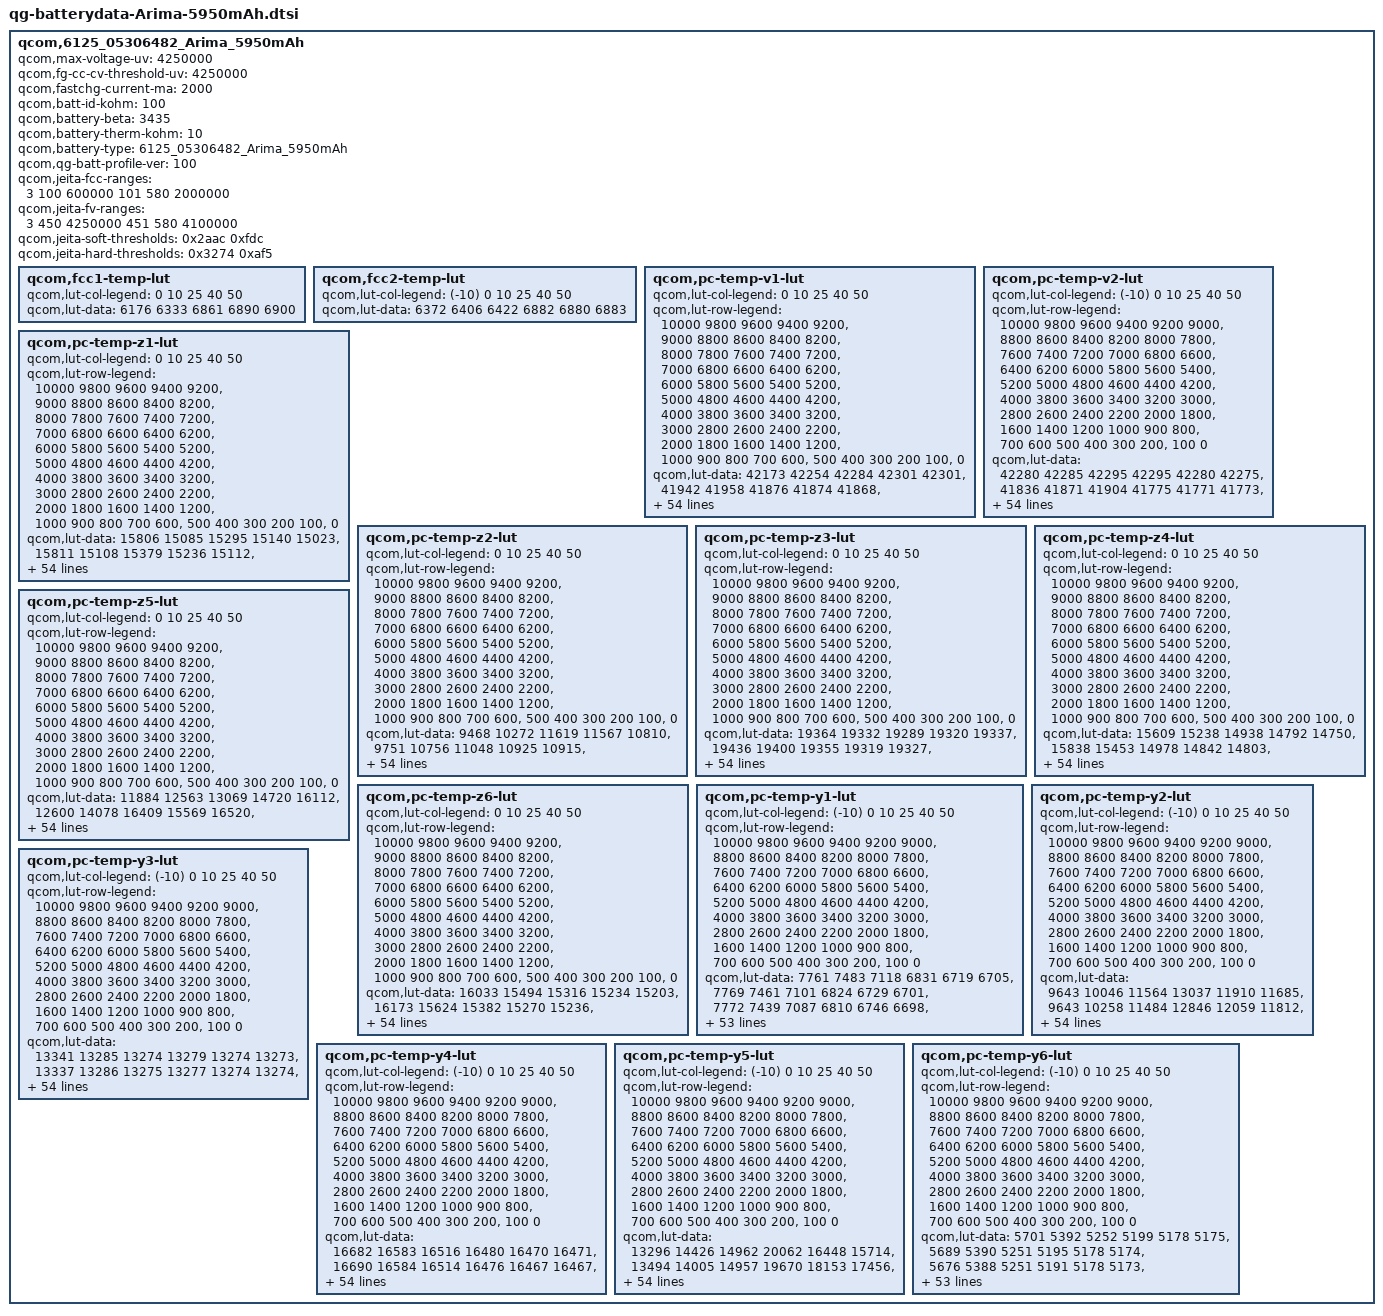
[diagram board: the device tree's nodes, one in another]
/* Copyright (c) 2022, Qualcomm Innovation Center, Inc. All rights reserved.
 *
 * This program is free software; you can redistribute it and/or modify
 * it under the terms of the GNU General Public License version 2 and
 * only version 2 as published by the Free Software Foundation.
 *
 * This program is distributed in the hope that it will be useful,
 * but WITHOUT ANY WARRANTY; without even the implied warranty of
 * MERCHANTABILITY or FITNESS FOR A PARTICULAR PURPOSE.  See the
 * GNU General Public License for more details.
 */

qcom,6125_05306482_Arima_5950mAh {
	/* 6125_05306482_Arima_5950mAh_averaged_MasterSlave_Oct2nd2021 */
	qcom,max-voltage-uv = <4250000>;
	qcom,fg-cc-cv-threshold-uv = <4250000>;
	qcom,fastchg-current-ma = <2000>;
	qcom,batt-id-kohm = <100>;
	qcom,battery-beta = <3435>;
	qcom,battery-therm-kohm = <10>;
	qcom,battery-type = "6125_05306482_Arima_5950mAh";
	qcom,qg-batt-profile-ver = <100>;
	qcom,jeita-fcc-ranges = <3   100   600000
				101 580  2000000>;

	qcom,jeita-fv-ranges =  <3   450  4250000
				451 580  4100000>;
	/* COOL = 10 DegC, WARM = 45 DegC */
	qcom,jeita-soft-thresholds = <0x2aac 0xfdc>;
	/* COLD = 3 DegC, HOT = 58 DegC */
	qcom,jeita-hard-thresholds = <0x3274 0xaf5>;

	qcom,fcc1-temp-lut {
		qcom,lut-col-legend = <0 10 25 40 50>;
		qcom,lut-data = <6176 6333 6861 6890 6900>;
	};

	qcom,fcc2-temp-lut {
		qcom,lut-col-legend = <(-10) 0 10 25 40 50>;
		qcom,lut-data = <6372 6406 6422 6882 6880 6883>;
	};

	qcom,pc-temp-v1-lut {
		qcom,lut-col-legend = <0 10 25 40 50>;
		qcom,lut-row-legend = <10000 9800 9600 9400 9200>,
			<9000 8800 8600 8400 8200>,
			<8000 7800 7600 7400 7200>,
			<7000 6800 6600 6400 6200>,
			<6000 5800 5600 5400 5200>,
			<5000 4800 4600 4400 4200>,
			<4000 3800 3600 3400 3200>,
			<3000 2800 2600 2400 2200>,
			<2000 1800 1600 1400 1200>,
			<1000 900 800 700 600>,
			<500 400 300 200 100>,
			<0>;
		qcom,lut-data = <42173 42254 42284 42301 42301>,
			<41942 41958 41876 41874 41868>,
			<41697 41677 41493 41489 41480>,
			<41451 41415 41168 41163 41154>,
			<41209 41175 40892 40875 40867>,
			<40957 40939 40632 40615 40610>,
			<40698 40707 40372 40370 40368>,
			<40436 40482 40134 40137 40142>,
			<40158 40258 39910 39913 39916>,
			<39901 40038 39692 39694 39693>,
			<39692 39828 39474 39477 39478>,
			<39511 39631 39266 39266 39268>,
			<39346 39445 39074 39057 39060>,
			<39195 39274 38902 38859 38858>,
			<39045 39118 38758 38680 38669>,
			<38895 38964 38625 38519 38491>,
			<38741 38810 38475 38383 38348>,
			<38575 38654 38310 38265 38231>,
			<38402 38487 38133 38124 38100>,
			<38230 38320 37944 37953 37949>,
			<38056 38154 37771 37784 37791>,
			<37886 37982 37615 37629 37635>,
			<37725 37813 37449 37459 37467>,
			<37575 37648 37242 37232 37247>,
			<37435 37488 37047 37021 37039>,
			<37306 37333 36889 36888 36904>,
			<37184 37172 36763 36784 36800>,
			<37071 37023 36674 36695 36712>,
			<36966 36901 36600 36619 36637>,
			<36869 36788 36531 36551 36569>,
			<36778 36687 36469 36491 36508>,
			<36691 36605 36410 36432 36449>,
			<36610 36533 36355 36374 36391>,
			<36534 36469 36299 36317 36334>,
			<36459 36411 36245 36264 36280>,
			<36384 36351 36189 36207 36221>,
			<36309 36291 36133 36144 36153>,
			<36232 36227 36070 36071 36073>,
			<36155 36152 35993 35981 35975>,
			<36073 36060 35898 35870 35858>,
			<35978 35941 35765 35733 35719>,
			<35862 35792 35598 35569 35555>,
			<35718 35621 35418 35384 35368>,
			<35547 35431 35219 35176 35158>,
			<35357 35239 34993 34948 34937>,
			<35186 35087 34812 34772 34760>,
			<35115 35031 34750 34704 34689>,
			<35054 34986 34696 34646 34631>,
			<34990 34931 34645 34591 34572>,
			<34917 34870 34588 34525 34501>,
			<34766 34710 34455 34361 34310>,
			<34373 34295 34073 33940 33876>,
			<33817 33748 33527 33373 33310>,
			<33104 33034 32796 32635 32565>,
			<32076 31989 31727 31547 31471>,
			<30000 30000 30000 30000 30000>;
	};

	qcom,pc-temp-v2-lut {
		qcom,lut-col-legend = <(-10) 0 10 25 40 50>;
		qcom,lut-row-legend = <10000 9800 9600 9400 9200 9000>,
			<8800 8600 8400 8200 8000 7800>,
			<7600 7400 7200 7000 6800 6600>,
			<6400 6200 6000 5800 5600 5400>,
			<5200 5000 4800 4600 4400 4200>,
			<4000 3800 3600 3400 3200 3000>,
			<2800 2600 2400 2200 2000 1800>,
			<1600 1400 1200 1000 900 800>,
			<700 600 500 400 300 200>,
			<100 0>;
		qcom,lut-data = <42280 42285 42295 42295 42280 42275>,
			<41836 41871 41904 41775 41771 41773>,
			<41458 41516 41566 41341 41343 41348>,
			<41157 41230 41289 41005 41005 41010>,
			<40903 40987 41049 40725 40721 40725>,
			<40652 40749 40813 40461 40456 40460>,
			<40403 40514 40582 40216 40212 40217>,
			<40161 40279 40356 39980 39977 39983>,
			<39926 40043 40134 39755 39753 39758>,
			<39693 39811 39915 39536 39534 39539>,
			<39461 39588 39703 39323 39320 39324>,
			<39234 39368 39502 39113 39110 39114>,
			<39013 39146 39304 38907 38904 38909>,
			<38795 38927 39104 38707 38706 38711>,
			<38574 38710 38899 38512 38515 38518>,
			<38353 38498 38688 38326 38335 38337>,
			<38141 38289 38464 38155 38175 38181>,
			<37936 38084 38239 37994 38030 38041>,
			<37736 37889 38027 37848 37893 37907>,
			<37540 37700 37822 37711 37760 37778>,
			<37354 37522 37634 37536 37614 37635>,
			<37177 37357 37458 37316 37454 37476>,
			<37011 37203 37298 37112 37263 37285>,
			<36856 37057 37155 36921 37011 37036>,
			<36710 36919 37025 36767 36813 36840>,
			<36575 36794 36904 36654 36688 36709>,
			<36452 36681 36789 36558 36589 36606>,
			<36339 36573 36682 36472 36506 36524>,
			<36235 36470 36581 36396 36435 36453>,
			<36136 36372 36488 36329 36371 36387>,
			<36044 36279 36403 36269 36313 36327>,
			<35956 36187 36324 36209 36257 36270>,
			<35875 36087 36249 36151 36203 36217>,
			<35797 35989 36174 36089 36141 36160>,
			<35719 35894 36099 36025 36074 36101>,
			<35643 35799 36021 35950 35997 36023>,
			<35572 35699 35938 35862 35907 35917>,
			<35501 35601 35850 35767 35796 35789>,
			<35428 35512 35753 35656 35670 35651>,
			<35351 35422 35643 35537 35538 35525>,
			<35268 35336 35523 35410 35411 35398>,
			<35157 35240 35381 35269 35277 35266>,
			<35036 35137 35230 35098 35109 35099>,
			<34912 35030 35067 34913 34920 34912>,
			<34764 34903 34919 34706 34713 34708>,
			<34598 34756 34790 34545 34561 34562>,
			<34510 34679 34730 34484 34506 34508>,
			<34407 34589 34667 34418 34451 34456>,
			<34286 34494 34593 34346 34383 34390>,
			<34128 34356 34489 34237 34291 34295>,
			<33912 34149 34290 34019 34079 34066>,
			<33601 33781 33894 33561 33614 33590>,
			<33094 33216 33301 32923 32985 32959>,
			<32348 32442 32522 32068 32136 32114>,
			<31346 31324 31410 30795 30907 30901>,
			<29473 29374 29468 29043 29084 29056>;
	};

	qcom,pc-temp-z1-lut {
		qcom,lut-col-legend = <0 10 25 40 50>;
		qcom,lut-row-legend = <10000 9800 9600 9400 9200>,
			<9000 8800 8600 8400 8200>,
			<8000 7800 7600 7400 7200>,
			<7000 6800 6600 6400 6200>,
			<6000 5800 5600 5400 5200>,
			<5000 4800 4600 4400 4200>,
			<4000 3800 3600 3400 3200>,
			<3000 2800 2600 2400 2200>,
			<2000 1800 1600 1400 1200>,
			<1000 900 800 700 600>,
			<500 400 300 200 100>,
			<0>;
		qcom,lut-data = <15806 15085 15295 15140 15023>,
			<15811 15108 15379 15236 15112>,
			<15805 15090 15401 15258 15145>,
			<15818 15094 15428 15279 15160>,
			<15807 15108 15441 15300 15172>,
			<15773 15103 15458 15302 15162>,
			<15776 15099 15448 15298 15154>,
			<15780 15099 15440 15305 15136>,
			<15776 15098 15439 15311 15138>,
			<15777 15097 15434 15311 15136>,
			<15785 15098 15419 15305 15123>,
			<15794 15101 15403 15300 15102>,
			<15799 15105 15397 15302 15091>,
			<15806 15109 15390 15307 15084>,
			<15808 15115 15367 15307 15077>,
			<15816 15119 15335 15305 15068>,
			<15832 15122 15318 15307 15054>,
			<15875 15126 15310 15315 15038>,
			<15921 15131 15293 15318 15022>,
			<15918 15139 15262 15318 15005>,
			<15896 15144 15226 15316 14987>,
			<15901 15148 15181 15313 14970>,
			<15908 15149 15136 15308 14953>,
			<15896 15153 15093 15302 14939>,
			<15880 15167 15055 15292 14924>,
			<15880 15177 15029 15275 14905>,
			<15889 15177 15006 15254 14881>,
			<15900 15175 14980 15234 14852>,
			<15905 15180 14952 15212 14819>,
			<15908 15192 14925 15188 14795>,
			<15924 15198 14900 15162 14779>,
			<15997 15197 14883 15124 14757>,
			<16033 15196 14872 15062 14727>,
			<15990 15197 14863 15004 14711>,
			<15949 15202 14855 14957 14708>,
			<15953 15210 14849 14908 14706>,
			<15963 15232 14846 14842 14698>,
			<15972 15246 14843 14791 14689>,
			<15981 15247 14838 14776 14682>,
			<15989 15246 14833 14767 14675>,
			<15998 15251 14828 14752 14669>,
			<16008 15269 14823 14736 14664>,
			<16010 15280 14819 14716 14657>,
			<15994 15271 14814 14693 14650>,
			<16016 15280 14809 14668 14650>,
			<16043 15308 14801 14646 14653>,
			<16060 15293 14799 14632 14658>,
			<16041 15301 14794 14618 14657>,
			<16021 15307 14797 14609 14651>,
			<16075 15306 14785 14603 14645>,
			<16083 15297 14793 14601 14637>,
			<16031 15331 14779 14601 14642>,
			<16078 15348 14791 14606 14655>,
			<16047 15373 14828 14617 14669>,
			<16047 15373 14828 14617 14669>,
			<16047 15373 14828 14617 14669>;
	};

	qcom,pc-temp-z2-lut {
		qcom,lut-col-legend = <0 10 25 40 50>;
		qcom,lut-row-legend = <10000 9800 9600 9400 9200>,
			<9000 8800 8600 8400 8200>,
			<8000 7800 7600 7400 7200>,
			<7000 6800 6600 6400 6200>,
			<6000 5800 5600 5400 5200>,
			<5000 4800 4600 4400 4200>,
			<4000 3800 3600 3400 3200>,
			<3000 2800 2600 2400 2200>,
			<2000 1800 1600 1400 1200>,
			<1000 900 800 700 600>,
			<500 400 300 200 100>,
			<0>;
		qcom,lut-data = <9468 10272 11619 11567 10810>,
			<9751 10756 11048 10925 10915>,
			<10068 11171 11643 11293 11081>,
			<10273 11232 11802 11453 11157>,
			<10410 11220 11817 11575 11310>,
			<11010 11201 11784 11484 11347>,
			<11047 11610 11958 11511 11330>,
			<11047 11465 11853 11703 11422>,
			<10985 11299 11850 11695 11470>,
			<10900 11236 11864 11682 11501>,
			<10808 11191 11908 11660 11482>,
			<10728 11139 11955 11645 11449>,
			<10764 11096 12006 11676 11515>,
			<10938 11094 12035 11720 11624>,
			<11012 11106 11993 11739 11612>,
			<10971 11123 11892 11763 11566>,
			<10880 11136 11753 11752 11557>,
			<10717 11122 11604 11666 11522>,
			<10416 10919 11587 11597 11489>,
			<10212 10588 11593 11491 11444>,
			<10173 10472 11586 11466 11437>,
			<10129 10457 11534 11550 11391>,
			<10061 10474 11491 11611 11357>,
			<9962 10571 11389 11694 11466>,
			<9742 10737 11324 11774 11570>,
			<9597 10844 11573 11644 11508>,
			<9596 10930 11843 11462 11382>,
			<9596 11202 11790 11459 11323>,
			<9614 11349 11691 11491 11307>,
			<9636 11310 11625 11459 11294>,
			<9638 11250 11516 11375 11217>,
			<9631 11120 11474 11368 11205>,
			<9646 11009 11441 11419 11266>,
			<10128 10914 11457 11476 11320>,
			<10595 10686 11506 11551 11352>,
			<10632 10687 11561 11651 11399>,
			<10653 10819 11639 11827 11555>,
			<10704 10920 11704 11941 11670>,
			<11258 10964 11736 11879 11621>,
			<12266 10996 11750 11790 11562>,
			<12606 11230 11716 11746 11567>,
			<12470 11655 11662 11672 11581>,
			<12099 11781 11605 11540 11508>,
			<12179 11707 11494 11376 11322>,
			<10412 11634 11482 11328 11316>,
			<10486 11348 11230 11159 11209>,
			<11391 11034 10836 10989 11040>,
			<11191 10598 10652 10885 10982>,
			<11146 10804 10547 10769 10816>,
			<10873 10767 10454 10696 10784>,
			<10627 10573 10451 10537 10570>,
			<9646 10866 10624 10363 10354>,
			<9804 10785 10268 10179 10218>,
			<9725 10552 10255 10044 10091>,
			<9725 10552 10255 10044 10091>,
			<9725 10552 10255 10044 10091>;
	};

	qcom,pc-temp-z3-lut {
		qcom,lut-col-legend = <0 10 25 40 50>;
		qcom,lut-row-legend = <10000 9800 9600 9400 9200>,
			<9000 8800 8600 8400 8200>,
			<8000 7800 7600 7400 7200>,
			<7000 6800 6600 6400 6200>,
			<6000 5800 5600 5400 5200>,
			<5000 4800 4600 4400 4200>,
			<4000 3800 3600 3400 3200>,
			<3000 2800 2600 2400 2200>,
			<2000 1800 1600 1400 1200>,
			<1000 900 800 700 600>,
			<500 400 300 200 100>,
			<0>;
		qcom,lut-data = <19364 19332 19289 19320 19337>,
			<19436 19400 19355 19319 19327>,
			<19472 19444 19370 19340 19338>,
			<19481 19474 19375 19335 19334>,
			<19483 19484 19369 19340 19337>,
			<19514 19481 19358 19337 19333>,
			<19526 19476 19363 19337 19330>,
			<19531 19480 19390 19352 19335>,
			<19533 19482 19374 19346 19335>,
			<19532 19479 19364 19340 19334>,
			<19523 19475 19363 19336 19332>,
			<19514 19465 19365 19335 19331>,
			<19517 19456 19371 19335 19331>,
			<19536 19452 19375 19337 19333>,
			<19551 19444 19368 19339 19332>,
			<19561 19432 19351 19342 19331>,
			<19568 19409 19331 19340 19329>,
			<19560 19393 19310 19332 19326>,
			<19521 19381 19307 19324 19323>,
			<19488 19362 19309 19317 19320>,
			<19482 19346 19310 19315 19319>,
			<19476 19336 19307 19315 19317>,
			<19469 19331 19307 19316 19316>,
			<19459 19334 19327 19335 19331>,
			<19440 19343 19346 19353 19348>,
			<19429 19353 19353 19350 19348>,
			<19429 19365 19356 19347 19346>,
			<19429 19383 19357 19346 19345>,
			<19424 19393 19356 19345 19341>,
			<19416 19393 19352 19339 19337>,
			<19411 19388 19343 19324 19327>,
			<19408 19374 19333 19320 19323>,
			<19404 19358 19319 19320 19321>,
			<19364 19345 19314 19320 19320>,
			<19327 19326 19314 19319 19318>,
			<19324 19319 19313 19318 19315>,
			<19321 19316 19309 19317 19311>,
			<19317 19314 19306 19317 19308>,
			<19298 19315 19307 19314 19307>,
			<19267 19319 19309 19311 19307>,
			<19257 19332 19317 19312 19308>,
			<19257 19359 19328 19313 19311>,
			<19257 19377 19332 19314 19314>,
			<19258 19385 19336 19316 19318>,
			<19266 19393 19354 19330 19323>,
			<19267 19386 19355 19323 19322>,
			<19259 19371 19348 19322 19325>,
			<19267 19342 19347 19326 19323>,
			<19269 19359 19346 19325 19324>,
			<19271 19359 19353 19329 19323>,
			<19271 19364 19361 19331 19335>,
			<19369 19412 19396 19351 19344>,
			<19455 19441 19403 19374 19349>,
			<19483 19452 19440 19379 19357>,
			<19483 19452 19440 19379 19357>,
			<19483 19452 19440 19379 19357>;
	};

	qcom,pc-temp-z4-lut {
		qcom,lut-col-legend = <0 10 25 40 50>;
		qcom,lut-row-legend = <10000 9800 9600 9400 9200>,
			<9000 8800 8600 8400 8200>,
			<8000 7800 7600 7400 7200>,
			<7000 6800 6600 6400 6200>,
			<6000 5800 5600 5400 5200>,
			<5000 4800 4600 4400 4200>,
			<4000 3800 3600 3400 3200>,
			<3000 2800 2600 2400 2200>,
			<2000 1800 1600 1400 1200>,
			<1000 900 800 700 600>,
			<500 400 300 200 100>,
			<0>;
		qcom,lut-data = <15609 15238 14938 14792 14750>,
			<15838 15453 14978 14842 14803>,
			<15904 15420 14943 14805 14779>,
			<15897 15332 14884 14778 14760>,
			<15868 15222 14858 14765 14750>,
			<15828 15130 14824 14757 14742>,
			<15739 15317 14818 14755 14744>,
			<15685 15234 14914 14805 14786>,
			<15699 15147 14884 14793 14780>,
			<15762 15096 14861 14779 14771>,
			<15809 15059 14849 14771 14765>,
			<15840 15042 14846 14765 14759>,
			<15815 15030 14855 14764 14754>,
			<15730 15012 14864 14766 14750>,
			<15636 14978 14850 14781 14757>,
			<15529 14949 14818 14809 14775>,
			<15432 14925 14790 14800 14776>,
			<15384 14906 14763 14751 14762>,
			<15355 14892 14745 14721 14745>,
			<15323 14879 14731 14705 14715>,
			<15283 14867 14725 14698 14700>,
			<15240 14856 14722 14696 14697>,
			<15202 14847 14725 14697 14697>,
			<15168 14843 14820 14781 14762>,
			<15140 14840 14915 14862 14830>,
			<15116 14839 14941 14846 14817>,
			<15090 14867 14943 14810 14787>,
			<15064 14898 14902 14785 14769>,
			<15040 14897 14844 14764 14754>,
			<15018 14903 14811 14752 14743>,
			<15003 14911 14787 14743 14735>,
			<14992 14898 14771 14732 14725>,
			<14987 14879 14757 14720 14714>,
			<14999 14861 14743 14708 14704>,
			<15009 14844 14727 14695 14693>,
			<15005 14828 14716 14689 14688>,
			<15001 14810 14711 14688 14692>,
			<14997 14800 14708 14688 14698>,
			<14996 14798 14711 14696 14704>,
			<15005 14803 14717 14708 14711>,
			<15014 14809 14727 14714 14715>,
			<15021 14815 14744 14718 14718>,
			<15035 14824 14758 14725 14722>,
			<15068 14850 14775 14735 14727>,
			<15086 14871 14808 14754 14739>,
			<15087 14855 14804 14752 14731>,
			<15094 14852 14801 14746 14721>,
			<15082 14856 14792 14734 14712>,
			<15077 14829 14780 14722 14698>,
			<15075 14830 14778 14720 14695>,
			<15116 14888 14811 14747 14716>,
			<15215 14957 14849 14764 14736>,
			<15267 14977 14884 14770 14746>,
			<15354 15014 14893 14791 14756>,
			<15354 15014 14893 14791 14756>,
			<15354 15014 14893 14791 14756>;
	};

	qcom,pc-temp-z5-lut {
		qcom,lut-col-legend = <0 10 25 40 50>;
		qcom,lut-row-legend = <10000 9800 9600 9400 9200>,
			<9000 8800 8600 8400 8200>,
			<8000 7800 7600 7400 7200>,
			<7000 6800 6600 6400 6200>,
			<6000 5800 5600 5400 5200>,
			<5000 4800 4600 4400 4200>,
			<4000 3800 3600 3400 3200>,
			<3000 2800 2600 2400 2200>,
			<2000 1800 1600 1400 1200>,
			<1000 900 800 700 600>,
			<500 400 300 200 100>,
			<0>;
		qcom,lut-data = <11884 12563 13069 14720 16112>,
			<12600 14078 16409 15569 16520>,
			<13639 15410 18829 18546 19089>,
			<14208 16619 20928 19525 20225>,
			<15026 17377 20961 21281 22345>,
			<17825 17877 20716 21895 22508>,
			<19195 16131 22047 22579 22315>,
			<19926 16333 20309 22610 21375>,
			<20811 16576 19770 22015 21861>,
			<21344 16836 19529 21441 22390>,
			<20450 17130 20039 21448 22469>,
			<18898 17314 20906 21564 22546>,
			<18300 17513 22479 21937 23244>,
			<18023 17681 23576 22596 24257>,
			<17674 18036 23002 23359 24105>,
			<17079 18317 21459 24189 23373>,
			<16552 17785 19315 24332 23123>,
			<15998 17396 16920 23564 23187>,
			<14995 16994 16781 22937 23224>,
			<14237 16022 17517 21789 24101>,
			<14004 15352 17808 21592 24738>,
			<13820 15020 17761 22291 24823>,
			<13670 14923 18106 22638 24508>,
			<13504 15257 22399 22137 23105>,
			<13245 16182 25286 21371 21463>,
			<13121 17186 22173 19925 20492>,
			<13246 18628 18546 18497 19824>,
			<13415 20685 18096 18980 20008>,
			<13541 21525 18001 19990 20684>,
			<13650 20995 17993 19666 20601>,
			<13755 20416 17817 18405 19756>,
			<13888 19092 17527 18323 19617>,
			<13964 17308 16815 19367 20431>,
			<13603 16008 16774 20458 21333>,
			<13280 14796 17684 21673 22624>,
			<13304 14680 18212 23013 23481>,
			<13311 14868 18342 24736 23560>,
			<13309 15100 18434 25744 23291>,
			<13034 15426 18588 24053 21964>,
			<12478 15943 18877 21763 20508>,
			<12334 17470 20126 21149 20389>,
			<12532 20117 21794 20674 20428>,
			<12668 21547 21286 19984 20424>,
			<12655 21506 20215 19338 20325>,
			<12728 21054 21077 20483 20044>,
			<12479 19467 19943 18298 19205>,
			<12427 17883 18293 17797 19590>,
			<12215 15351 17777 18255 19376>,
			<12140 16435 17457 18499 20525>,
			<12117 16232 17959 19420 21115>,
			<12159 15714 17264 16938 19100>,
			<14028 16018 17333 16711 17456>,
			<14645 15844 15904 17871 16706>,
			<14053 14865 16706 16640 16130>,
			<14053 14865 16706 16640 16130>,
			<14053 14865 16706 16640 16130>;
	};

	qcom,pc-temp-z6-lut {
		qcom,lut-col-legend = <0 10 25 40 50>;
		qcom,lut-row-legend = <10000 9800 9600 9400 9200>,
			<9000 8800 8600 8400 8200>,
			<8000 7800 7600 7400 7200>,
			<7000 6800 6600 6400 6200>,
			<6000 5800 5600 5400 5200>,
			<5000 4800 4600 4400 4200>,
			<4000 3800 3600 3400 3200>,
			<3000 2800 2600 2400 2200>,
			<2000 1800 1600 1400 1200>,
			<1000 900 800 700 600>,
			<500 400 300 200 100>,
			<0>;
		qcom,lut-data = <16033 15494 15316 15234 15203>,
			<16173 15624 15382 15270 15236>,
			<16213 15632 15379 15270 15237>,
			<16202 15606 15360 15258 15229>,
			<16185 15566 15348 15258 15227>,
			<16180 15527 15330 15253 15220>,
			<16154 15602 15329 15251 15217>,
			<16140 15567 15383 15282 15235>,
			<16148 15531 15362 15274 15233>,
			<16176 15510 15345 15265 15228>,
			<16199 15493 15336 15258 15221>,
			<16214 15479 15333 15254 15215>,
			<16207 15470 15339 15254 15211>,
			<16184 15460 15343 15256 15209>,
			<16155 15444 15331 15264 15210>,
			<16119 15425 15302 15277 15214>,
			<16088 15402 15277 15273 15214>,
			<16064 15385 15253 15249 15203>,
			<16035 15374 15240 15232 15191>,
			<16005 15360 15231 15221 15173>,
			<15985 15346 15221 15217 15163>,
			<15972 15336 15209 15216 15157>,
			<15959 15330 15206 15216 15154>,
			<15939 15330 15249 15262 15189>,
			<15914 15337 15293 15306 15225>,
			<15902 15346 15306 15296 15218>,
			<15900 15367 15305 15274 15199>,
			<15898 15389 15283 15259 15185>,
			<15886 15395 15254 15246 15171>,
			<15868 15402 15232 15232 15159>,
			<15866 15406 15213 15217 15148>,
			<15873 15394 15197 15202 15137>,
			<15877 15379 15183 15186 15126>,
			<15867 15365 15172 15170 15118>,
			<15855 15350 15163 15156 15111>,
			<15859 15341 15157 15144 15108>,
			<15872 15334 15152 15131 15106>,
			<15875 15331 15150 15122 15104>,
			<15871 15333 15152 15123 15105>,
			<15864 15339 15156 15125 15107>,
			<15871 15353 15165 15126 15109>,
			<15885 15374 15180 15127 15111>,
			<15899 15393 15191 15128 15113>,
			<15921 15414 15202 15130 15117>,
			<15935 15433 15230 15143 15127>,
			<15951 15427 15233 15137 15124>,
			<15958 15421 15230 15133 15123>,
			<15957 15409 15227 15130 15118>,
			<15963 15410 15224 15124 15114>,
			<15968 15417 15228 15126 15112>,
			<15998 15451 15251 15141 15128>,
			<16096 15516 15290 15164 15146>,
			<16176 15551 15315 15183 15158>,
			<16264 15589 15352 15201 15173>,
			<16264 15589 15352 15201 15173>,
			<16264 15589 15352 15201 15173>;
	};

	qcom,pc-temp-y1-lut {
		qcom,lut-col-legend = <(-10) 0 10 25 40 50>;
		qcom,lut-row-legend = <10000 9800 9600 9400 9200 9000>,
			<8800 8600 8400 8200 8000 7800>,
			<7600 7400 7200 7000 6800 6600>,
			<6400 6200 6000 5800 5600 5400>,
			<5200 5000 4800 4600 4400 4200>,
			<4000 3800 3600 3400 3200 3000>,
			<2800 2600 2400 2200 2000 1800>,
			<1600 1400 1200 1000 900 800>,
			<700 600 500 400 300 200>,
			<100 0>;
		qcom,lut-data = <7761 7483 7118 6831 6719 6705>,
			<7769 7461 7101 6824 6729 6701>,
			<7772 7439 7087 6810 6746 6698>,
			<7772 7421 7078 6795 6762 6695>,
			<7770 7408 7074 6786 6773 6693>,
			<7768 7408 7075 6786 6774 6690>,
			<7757 7424 7080 6787 6774 6688>,
			<7745 7428 7077 6788 6775 6689>,
			<7746 7418 7072 6788 6777 6693>,
			<7755 7413 7069 6788 6778 6696>,
			<7769 7413 7073 6789 6781 6703>,
			<7774 7415 7082 6789 6783 6707>,
			<7766 7428 7092 6797 6784 6708>,
			<7761 7442 7093 6808 6785 6709>,
			<7762 7442 7088 6816 6786 6712>,
			<7765 7443 7086 6823 6788 6715>,
			<7771 7448 7092 6831 6789 6715>,
			<7785 7447 7101 6838 6791 6714>,
			<7790 7446 7104 6835 6791 6715>,
			<7786 7451 7106 6829 6788 6719>,
			<7785 7452 7106 6829 6788 6720>,
			<7810 7444 7107 6837 6789 6720>,
			<7836 7440 7110 6839 6790 6721>,
			<7834 7444 7114 6838 6795 6723>,
			<7825 7452 7118 6838 6796 6725>,
			<7824 7459 7122 6844 6793 6726>,
			<7810 7456 7124 6848 6791 6726>,
			<7800 7446 7124 6848 6793 6726>,
			<7821 7445 7123 6849 6797 6726>,
			<7842 7455 7123 6851 6800 6728>,
			<7837 7459 7126 6853 6802 6732>,
			<7829 7461 7130 6853 6801 6733>,
			<7837 7465 7137 6852 6800 6733>,
			<7846 7466 7141 6853 6801 6734>,
			<7848 7470 7143 6859 6805 6735>,
			<7846 7478 7144 6861 6809 6737>,
			<7846 7477 7144 6861 6811 6741>,
			<7847 7477 7145 6861 6810 6740>,
			<7877 7476 7151 6861 6809 6740>,
			<7875 7472 7155 6867 6813 6745>,
			<7849 7485 7158 6868 6818 6749>,
			<7886 7496 7166 6871 6821 6748>,
			<7904 7506 7168 6874 6820 6752>,
			<7954 7517 7170 6881 6828 6759>,
			<8029 7533 7175 6888 6833 6763>,
			<8012 7560 7178 6902 6838 6766>,
			<8005 7567 7187 6893 6839 6772>,
			<8034 7567 7192 6894 6842 6777>,
			<8100 7585 7204 6901 6849 6779>,
			<8094 7596 7212 6903 6853 6783>,
			<8107 7604 7227 6910 6858 6785>,
			<8124 7621 7226 6927 6866 6789>,
			<8177 7633 7237 6952 6875 6801>,
			<8141 7647 7251 6977 6887 6817>,
			<8141 7647 7251 6977 6887 6817>,
			<8141 7647 7251 6977 6887 6817>;
	};

	qcom,pc-temp-y2-lut {
		qcom,lut-col-legend = <(-10) 0 10 25 40 50>;
		qcom,lut-row-legend = <10000 9800 9600 9400 9200 9000>,
			<8800 8600 8400 8200 8000 7800>,
			<7600 7400 7200 7000 6800 6600>,
			<6400 6200 6000 5800 5600 5400>,
			<5200 5000 4800 4600 4400 4200>,
			<4000 3800 3600 3400 3200 3000>,
			<2800 2600 2400 2200 2000 1800>,
			<1600 1400 1200 1000 900 800>,
			<700 600 500 400 300 200>,
			<100 0>;
		qcom,lut-data = <9643 10046 11564 13037 11910 11685>,
			<9643 10258 11484 12846 12059 11812>,
			<9753 10544 11426 12637 12151 11910>,
			<10075 10851 11386 12442 12193 11974>,
			<10346 11130 11357 12296 12192 11995>,
			<10508 11346 11327 12221 12134 11962>,
			<10586 11514 11361 12171 12026 11890>,
			<10653 11520 11497 12089 11983 11855>,
			<10736 11276 11674 11961 11968 11839>,
			<10788 11223 11810 11934 11949 11807>,
			<10796 11543 11919 12041 11900 11703>,
			<10798 11781 12024 12135 11850 11650>,
			<11055 11820 12097 12185 11802 11663>,
			<11419 11861 12129 12232 11776 11677>,
			<11292 11919 12157 12287 11853 11705>,
			<10915 11969 12186 12359 11963 11743>,
			<10850 11999 12213 12471 12008 11776>,
			<10875 12023 12245 12598 12046 11821>,
			<10883 12055 12292 12697 12134 11879>,
			<10872 12099 12377 12798 12294 11962>,
			<10853 12149 12451 12788 12480 12120>,
			<10802 12207 12507 12650 12701 12394>,
			<10747 12264 12567 12606 12720 12445>,
			<10721 12311 12648 12643 12444 12292>,
			<10709 12351 12734 12674 12326 12220>,
			<10710 12386 12775 12777 12470 12286>,
			<10724 12421 12798 12868 12570 12325>,
			<10737 12433 12831 12851 12555 12419>,
			<10725 12419 12878 12826 12536 12555>,
			<10689 12399 12917 12906 12683 12569>,
			<10655 12371 12933 13050 12953 12577>,
			<10638 12231 12935 13103 13009 12645>,
			<10633 11504 12924 13130 13002 12795>,
			<10624 11099 12892 13116 12957 12888>,
			<10608 11588 12808 13028 12872 12958>,
			<10591 12045 12728 12933 12832 12937>,
			<10575 11987 12672 12847 12838 12762>,
			<10556 11892 12623 12825 12748 12483>,
			<10527 11812 12580 12792 12639 12295>,
			<10469 11676 12542 12690 12428 12286>,
			<10336 11170 12387 12482 12306 12163>,
			<9891 10945 12205 12177 12120 12142>,
			<9711 10796 11900 11770 12096 12045>,
			<9686 10706 11431 11602 11900 11892>,
			<9678 10643 11283 11078 11656 11747>,
			<9673 10621 10982 10812 11348 11440>,
			<9671 10572 10885 10588 11213 11318>,
			<9668 10515 10829 10383 11092 11181>,
			<9666 10469 10805 10453 10983 11117>,
			<9664 10392 10797 10113 11103 11194>,
			<9664 10297 10726 9813 10942 11128>,
			<9662 10170 10587 9718 10579 10791>,
			<9662 9751 10441 9678 10390 10670>,
			<9662 9707 10347 9700 10171 10504>,
			<9662 9707 10347 9700 10171 10504>,
			<9662 9707 10347 9700 10171 10504>;
	};

	qcom,pc-temp-y3-lut {
		qcom,lut-col-legend = <(-10) 0 10 25 40 50>;
		qcom,lut-row-legend = <10000 9800 9600 9400 9200 9000>,
			<8800 8600 8400 8200 8000 7800>,
			<7600 7400 7200 7000 6800 6600>,
			<6400 6200 6000 5800 5600 5400>,
			<5200 5000 4800 4600 4400 4200>,
			<4000 3800 3600 3400 3200 3000>,
			<2800 2600 2400 2200 2000 1800>,
			<1600 1400 1200 1000 900 800>,
			<700 600 500 400 300 200>,
			<100 0>;
		qcom,lut-data = <13341 13285 13274 13279 13274 13273>,
			<13337 13286 13275 13277 13274 13274>,
			<13334 13288 13276 13275 13274 13274>,
			<13332 13291 13278 13273 13274 13274>,
			<13331 13295 13279 13272 13274 13274>,
			<13329 13298 13280 13272 13274 13275>,
			<13329 13304 13281 13274 13274 13275>,
			<13330 13306 13282 13274 13274 13276>,
			<13330 13303 13285 13274 13275 13277>,
			<13330 13303 13288 13274 13276 13277>,
			<13329 13308 13292 13277 13276 13277>,
			<13330 13312 13298 13280 13276 13277>,
			<13333 13313 13304 13283 13277 13278>,
			<13337 13313 13307 13285 13277 13278>,
			<13336 13313 13307 13287 13280 13279>,
			<13332 13313 13307 13289 13283 13280>,
			<13332 13312 13305 13290 13286 13283>,
			<13333 13311 13302 13291 13289 13286>,
			<13333 13310 13299 13291 13290 13287>,
			<13333 13309 13296 13291 13291 13287>,
			<13333 13309 13293 13290 13290 13287>,
			<13332 13309 13289 13286 13287 13286>,
			<13331 13310 13286 13282 13283 13283>,
			<13330 13309 13285 13276 13276 13276>,
			<13327 13308 13287 13272 13273 13272>,
			<13324 13308 13288 13272 13273 13271>,
			<13322 13310 13288 13272 13273 13271>,
			<13322 13311 13288 13271 13272 13271>,
			<13323 13310 13288 13271 13271 13272>,
			<13324 13310 13288 13273 13272 13271>,
			<13327 13310 13290 13277 13273 13270>,
			<13332 13310 13292 13279 13274 13271>,
			<13339 13305 13293 13280 13275 13272>,
			<13348 13302 13294 13280 13275 13274>,
			<13362 13307 13295 13280 13276 13275>,
			<13378 13311 13295 13280 13276 13276>,
			<13402 13309 13296 13280 13277 13275>,
			<13439 13308 13297 13281 13276 13274>,
			<13492 13310 13297 13280 13275 13272>,
			<13584 13309 13296 13278 13273 13272>,
			<13583 13307 13295 13278 13273 13272>,
			<13783 13322 13294 13277 13273 13273>,
			<14091 13352 13294 13277 13274 13273>,
			<14776 13439 13293 13279 13274 13274>,
			<16032 13734 13302 13280 13274 13274>,
			<18427 14353 13336 13287 13277 13276>,
			<20239 14837 13387 13292 13278 13277>,
			<22476 15502 13509 13301 13282 13281>,
			<25294 16539 13768 13319 13285 13284>,
			<27905 17630 14130 13340 13293 13287>,
			<30864 19229 14546 13403 13295 13287>,
			<33674 20677 15022 13601 13294 13286>,
			<34890 21835 15487 14068 13304 13289>,
			<34046 21839 15665 14487 13322 13297>,
			<34046 21839 15665 14487 13322 13297>,
			<34046 21839 15665 14487 13322 13297>;
	};

	qcom,pc-temp-y4-lut {
		qcom,lut-col-legend = <(-10) 0 10 25 40 50>;
		qcom,lut-row-legend = <10000 9800 9600 9400 9200 9000>,
			<8800 8600 8400 8200 8000 7800>,
			<7600 7400 7200 7000 6800 6600>,
			<6400 6200 6000 5800 5600 5400>,
			<5200 5000 4800 4600 4400 4200>,
			<4000 3800 3600 3400 3200 3000>,
			<2800 2600 2400 2200 2000 1800>,
			<1600 1400 1200 1000 900 800>,
			<700 600 500 400 300 200>,
			<100 0>;
		qcom,lut-data = <16682 16583 16516 16480 16470 16471>,
			<16690 16584 16514 16476 16467 16467>,
			<16698 16587 16515 16473 16462 16462>,
			<16705 16592 16518 16471 16457 16458>,
			<16712 16595 16523 16470 16454 16455>,
			<16718 16596 16530 16470 16453 16454>,
			<16725 16598 16539 16470 16454 16453>,
			<16729 16601 16548 16473 16454 16453>,
			<16729 16613 16554 16482 16456 16453>,
			<16729 16618 16559 16488 16457 16453>,
			<16730 16611 16564 16491 16462 16455>,
			<16732 16606 16571 16495 16467 16458>,
			<16724 16606 16578 16501 16472 16461>,
			<16712 16606 16583 16509 16477 16464>,
			<16713 16605 16586 16520 16481 16467>,
			<16719 16604 16588 16533 16485 16472>,
			<16718 16602 16578 16552 16496 16482>,
			<16711 16599 16560 16576 16512 16496>,
			<16704 16597 16546 16602 16526 16505>,
			<16697 16595 16533 16626 16539 16512>,
			<16692 16592 16526 16619 16554 16524>,
			<16687 16589 16524 16566 16570 16540>,
			<16685 16587 16522 16521 16566 16538>,
			<16687 16586 16521 16482 16499 16489>,
			<16695 16587 16519 16465 16457 16457>,
			<16702 16586 16517 16462 16447 16448>,
			<16709 16587 16516 16461 16444 16444>,
			<16716 16588 16518 16464 16448 16447>,
			<16728 16590 16521 16469 16455 16451>,
			<16744 16592 16524 16472 16462 16458>,
			<16759 16593 16528 16476 16470 16468>,
			<16774 16596 16534 16482 16479 16476>,
			<16791 16608 16542 16491 16490 16485>,
			<16809 16610 16551 16501 16496 16495>,
			<16829 16590 16560 16510 16501 16506>,
			<16852 16573 16566 16512 16501 16507>,
			<16878 16573 16570 16507 16497 16497>,
			<16905 16577 16571 16501 16485 16479>,
			<16926 16586 16569 16490 16471 16466>,
			<16940 16609 16553 16472 16459 16459>,
			<16903 16623 16538 16469 16457 16458>,
			<16995 16648 16525 16474 16464 16462>,
			<17125 16683 16523 16474 16460 16458>,
			<17396 16722 16531 16479 16461 16457>,
			<17906 16777 16545 16483 16455 16448>,
			<18964 16968 16583 16498 16459 16452>,
			<19874 17176 16621 16522 16473 16464>,
			<21201 17486 16664 16556 16487 16476>,
			<23413 17997 16738 16586 16505 16492>,
			<26899 18681 16901 16645 16522 16513>,
			<33011 19914 17133 16706 16526 16506>,
			<40926 21865 17476 16752 16511 16483>,
			<51482 25044 18215 17000 16531 16489>,
			<65535 30235 19816 17719 16573 16504>,
			<65535 30235 19816 17719 16573 16504>,
			<65535 30235 19816 17719 16573 16504>;
	};

	qcom,pc-temp-y5-lut {
		qcom,lut-col-legend = <(-10) 0 10 25 40 50>;
		qcom,lut-row-legend = <10000 9800 9600 9400 9200 9000>,
			<8800 8600 8400 8200 8000 7800>,
			<7600 7400 7200 7000 6800 6600>,
			<6400 6200 6000 5800 5600 5400>,
			<5200 5000 4800 4600 4400 4200>,
			<4000 3800 3600 3400 3200 3000>,
			<2800 2600 2400 2200 2000 1800>,
			<1600 1400 1200 1000 900 800>,
			<700 600 500 400 300 200>,
			<100 0>;
		qcom,lut-data = <13296 14426 14962 20062 16448 15714>,
			<13494 14005 14957 19670 18153 17456>,
			<13647 13896 14782 18559 19446 19765>,
			<13772 13998 14526 17310 20304 22017>,
			<13885 14209 14279 16503 20702 23589>,
			<13979 14569 14082 16429 20534 24232>,
			<14048 15219 13890 16390 19914 24658>,
			<14198 15434 13904 16119 19597 24652>,
			<14454 15059 14167 15289 19522 24233>,
			<14626 14993 14677 15067 19203 23516>,
			<14718 16066 15529 15615 18254 21635>,
			<14889 17010 17283 16126 17462 20322>,
			<15515 17318 19756 16613 16927 19643>,
			<16281 17616 21803 16890 16672 19305>,
			<16261 17982 23468 17254 17548 19235>,
			<15884 18222 24352 17853 18676 19091>,
			<16086 18343 24091 18352 19409 19570>,
			<16387 18447 23600 19071 20295 20477>,
			<16443 18545 23053 20386 20302 20593>,
			<16425 18674 21938 22542 20006 20308>,
			<16355 18870 20771 24290 20426 20311>,
			<16044 19464 19236 25792 21867 20395>,
			<15596 19969 18240 25634 22425 20796>,
			<15092 20102 18462 21335 22381 22039>,
			<14417 20211 19350 18708 22482 22927>,
			<13955 20493 20124 18420 23033 22467>,
			<13625 21281 20515 18421 23401 21753>,
			<13487 21908 20354 18173 21833 21123>,
			<13392 22104 20284 17861 20073 20487>,
			<13261 22275 20589 19497 20487 19470>,
			<13214 22604 21501 22720 21440 18280>,
			<13233 22712 22493 24394 22166 18408>,
			<13300 20737 23374 25442 22804 19335>,
			<13446 19499 23739 25740 23255 20828>,
			<13675 20446 23919 25843 23630 22970>,
			<13899 21153 24098 25809 24295 23871>,
			<14178 19224 24217 25556 25506 24472>,
			<14518 17272 24315 25932 25231 23309>,
			<14850 16455 24348 24881 24391 21039>,
			<15116 15068 23908 23901 21275 20993>,
			<15066 14255 23516 22967 21102 20311>,
			<13770 14219 21903 20288 19480 20143>,
			<12889 14195 19955 18820 20243 20188>,
			<12442 14890 16506 18411 18901 20110>,
			<12069 15032 15675 16845 19177 21552>,
			<11904 14949 15428 15638 17853 19500>,
			<11881 14829 15070 15025 16269 17536>,
			<11843 14369 15010 14353 16280 18082>,
			<11757 14425 15268 15020 15937 17827>,
			<11373 14468 15525 13951 17215 18101>,
			<10990 14244 15320 13422 17157 17768>,
			<10487 13055 13396 13164 15836 17138>,
			<10048 11370 12046 12075 15675 16581>,
			<9597 11162 12145 10566 14803 16903>,
			<9597 11162 12145 10566 14803 16903>,
			<9597 11162 12145 10566 14803 16903>;
	};

	qcom,pc-temp-y6-lut {
		qcom,lut-col-legend = <(-10) 0 10 25 40 50>;
		qcom,lut-row-legend = <10000 9800 9600 9400 9200 9000>,
			<8800 8600 8400 8200 8000 7800>,
			<7600 7400 7200 7000 6800 6600>,
			<6400 6200 6000 5800 5600 5400>,
			<5200 5000 4800 4600 4400 4200>,
			<4000 3800 3600 3400 3200 3000>,
			<2800 2600 2400 2200 2000 1800>,
			<1600 1400 1200 1000 900 800>,
			<700 600 500 400 300 200>,
			<100 0>;
		qcom,lut-data = <5701 5392 5252 5199 5178 5175>,
			<5689 5390 5251 5195 5178 5174>,
			<5676 5388 5251 5191 5178 5173>,
			<5666 5388 5252 5188 5178 5171>,
			<5660 5388 5254 5186 5178 5170>,
			<5658 5390 5257 5186 5178 5170>,
			<5662 5393 5260 5187 5179 5170>,
			<5664 5396 5263 5189 5179 5170>,
			<5661 5397 5267 5191 5181 5171>,
			<5656 5397 5270 5194 5182 5173>,
			<5656 5399 5274 5197 5184 5174>,
			<5659 5400 5281 5200 5185 5175>,
			<5659 5401 5288 5205 5187 5176>,
			<5657 5402 5290 5210 5189 5178>,
			<5656 5403 5292 5215 5192 5180>,
			<5656 5402 5293 5221 5196 5183>,
			<5655 5400 5289 5228 5202 5187>,
			<5653 5398 5282 5236 5208 5193>,
			<5652 5398 5277 5243 5213 5197>,
			<5652 5397 5271 5249 5217 5199>,
			<5652 5397 5267 5247 5220 5202>,
			<5649 5396 5264 5229 5222 5206>,
			<5646 5396 5261 5213 5219 5204>,
			<5647 5396 5261 5197 5195 5184>,
			<5650 5397 5261 5190 5180 5172>,
			<5653 5397 5262 5189 5177 5169>,
			<5654 5398 5263 5189 5176 5168>,
			<5656 5400 5263 5190 5177 5168>,
			<5662 5403 5264 5191 5179 5170>,
			<5673 5404 5266 5194 5181 5172>,
			<5682 5405 5269 5198 5185 5174>,
			<5691 5406 5273 5201 5188 5177>,
			<5702 5407 5277 5205 5191 5181>,
			<5718 5406 5280 5208 5194 5185>,
			<5742 5406 5284 5212 5196 5190>,
			<5769 5408 5287 5212 5196 5190>,
			<5802 5411 5290 5212 5196 5187>,
			<5847 5415 5292 5211 5193 5181>,
			<5907 5425 5292 5207 5188 5177>,
			<5999 5438 5289 5203 5183 5175>,
			<6000 5445 5287 5203 5184 5175>,
			<6188 5476 5286 5204 5186 5177>,
			<6474 5523 5289 5206 5186 5177>,
			<7077 5626 5296 5212 5188 5178>,
			<8127 5875 5317 5218 5187 5176>,
			<10093 6393 5378 5233 5193 5180>,
			<11591 6802 5445 5248 5199 5186>,
			<13494 7349 5565 5270 5207 5193>,
			<16048 8209 5784 5304 5217 5200>,
			<18818 9146 6095 5355 5229 5210>,
			<22593 10589 6458 5452 5234 5209>,
			<26700 12130 6892 5658 5233 5203>,
			<30776 13817 7432 6093 5253 5210>,
			<34999 15437 8042 6642 5289 5224>,
			<34999 15437 8042 6642 5289 5224>,
			<34999 15437 8042 6642 5289 5224>;
	};

};
